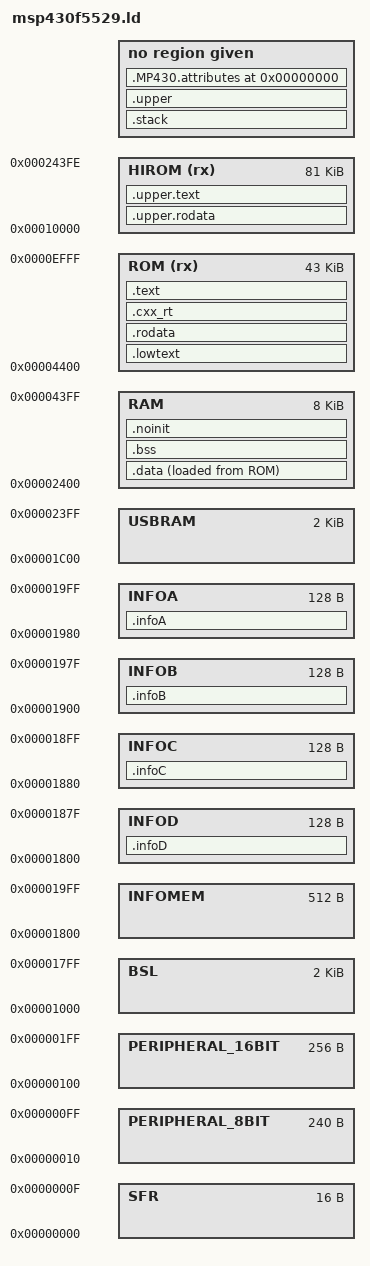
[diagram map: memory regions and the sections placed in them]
/* ============================================================================ */
/* Copyright (c) 2015, Texas Instruments Incorporated                           */
/*  All rights reserved.                                                        */
/*                                                                              */
/*  Redistribution and use in source and binary forms, with or without          */
/*  modification, are permitted provided that the following conditions          */
/*  are met:                                                                    */
/*                                                                              */
/*  *  Redistributions of source code must retain the above copyright           */
/*     notice, this list of conditions and the following disclaimer.            */
/*                                                                              */
/*  *  Redistributions in binary form must reproduce the above copyright        */
/*     notice, this list of conditions and the following disclaimer in the      */
/*     documentation and/or other materials provided with the distribution.     */
/*                                                                              */
/*  *  Neither the name of Texas Instruments Incorporated nor the names of      */
/*     its contributors may be used to endorse or promote products derived      */
/*     from this software without specific prior written permission.            */
/*                                                                              */
/*  THIS SOFTWARE IS PROVIDED BY THE COPYRIGHT HOLDERS AND CONTRIBUTORS "AS IS" */
/*  AND ANY EXPRESS OR IMPLIED WARRANTIES, INCLUDING, BUT NOT LIMITED TO,       */
/*  THE IMPLIED WARRANTIES OF MERCHANTABILITY AND FITNESS FOR A PARTICULAR      */
/*  PURPOSE ARE DISCLAIMED. IN NO EVENT SHALL THE COPYRIGHT OWNER OR            */
/*  CONTRIBUTORS BE LIABLE FOR ANY DIRECT, INDIRECT, INCIDENTAL, SPECIAL,       */
/*  EXEMPLARY, OR CONSEQUENTIAL DAMAGES (INCLUDING, BUT NOT LIMITED TO,         */
/*  PROCUREMENT OF SUBSTITUTE GOODS OR SERVICES; LOSS OF USE, DATA, OR PROFITS; */
/*  OR BUSINESS INTERRUPTION) HOWEVER CAUSED AND ON ANY THEORY OF LIABILITY,    */
/*  WHETHER IN CONTRACT, STRICT LIABILITY, OR TORT (INCLUDING NEGLIGENCE OR     */
/*  OTHERWISE) ARISING IN ANY WAY OUT OF THE USE OF THIS SOFTWARE,              */
/*  EVEN IF ADVISED OF THE POSSIBILITY OF SUCH DAMAGE.                          */
/* ============================================================================ */

/* This file supports MSP430F5529 devices. */
/* Version: 1.159 */
/* Default linker script, for normal executables */

OUTPUT_ARCH(msp430)
ENTRY(_start)

MEMORY {
  SFR              : ORIGIN = 0x0000, LENGTH = 0x0010 /* END=0x0010, size 16 */
  PERIPHERAL_8BIT  : ORIGIN = 0x0010, LENGTH = 0x00F0 /* END=0x0100, size 240 */
  PERIPHERAL_16BIT : ORIGIN = 0x0100, LENGTH = 0x0100 /* END=0x0200, size 256 */
  RAM              : ORIGIN = 0x2400, LENGTH = 0x2000 /* END=0x43FF, size 8192 */
  INFOMEM          : ORIGIN = 0x1800, LENGTH = 0x0200 /* END=0x19FF, size 512 as 4 128-byte segments */
  INFOA            : ORIGIN = 0x1980, LENGTH = 0x0080 /* END=0x19FF, size 128 */
  INFOB            : ORIGIN = 0x1900, LENGTH = 0x0080 /* END=0x197F, size 128 */
  INFOC            : ORIGIN = 0x1880, LENGTH = 0x0080 /* END=0x18FF, size 128 */
  INFOD            : ORIGIN = 0x1800, LENGTH = 0x0080 /* END=0x187F, size 128 */
  ROM (rx)       : ORIGIN = 0x4400, LENGTH = 0xac00 /* END=0xF3FF, size 44032 */
  BSL              : ORIGIN = 0x1000, LENGTH = 0x0800
  USBRAM           : ORIGIN = 0x1C00, LENGTH = 0x0800
  HIROM (rx)     : ORIGIN = 0x00010000, LENGTH = 0x000143FF
}

SECTIONS
{
  /* This is just for crt0.S and interrupt handlers.  */
  .lowtext           :
  {
    PROVIDE (_start = .);
    . = ALIGN(2);
    KEEP (*(SORT(.crt_*)))
    . = ALIGN(2);
    KEEP (*(.lowtext))
  } > ROM

  .rodata :
  {
    . = ALIGN(2);
    *(.plt)
    . = ALIGN(2);
    *(.lower.rodata.* .lower.rodata)
    . = ALIGN(2);
    *(.rodata .rodata.* .gnu.linkonce.r.* .const .const:*)
    . = ALIGN(2);
    *(.rodata1)

  } > ROM

  .cxx_rt :
  {
    . = ALIGN(2);
    *(.eh_frame_hdr)
    . = ALIGN(2);
    KEEP (*(.eh_frame))
    . = ALIGN(2);
    KEEP (*(.gcc_except_table)) *(.gcc_except_table.*)
    . = ALIGN(2);
    PROVIDE (__preinit_array_start = .);
    . = ALIGN(2);
    KEEP (*(.preinit_array))
    . = ALIGN(2);
    PROVIDE (__preinit_array_end = .);
    . = ALIGN(2);
    PROVIDE (__init_array_start = .);
    . = ALIGN(2);
    KEEP (*(SORT(.init_array.*)))
    . = ALIGN(2);
    KEEP (*(.init_array))
    . = ALIGN(2);
    PROVIDE (__init_array_end = .);
    . = ALIGN(2);
    PROVIDE (__fini_array_start = .);
    . = ALIGN(2);
    KEEP (*(.fini_array))
    . = ALIGN(2);
    KEEP (*(SORT(.fini_array.*)))
    . = ALIGN(2);
    PROVIDE (__fini_array_end = .);
    . = ALIGN(2);
    LONG(0); /* Sentinel.  */
    . = ALIGN(2);

    /* gcc uses crtbegin.o to find the start of the constructors, so
       we make sure it is first.  Because this is a wildcard, it
       doesn't matter if the user does not actually link against
       crtbegin.o; the linker won't look for a file to match a
       wildcard.  The wildcard also means that it doesn't matter which
       directory crtbegin.o is in.  */
    KEEP (*crtbegin*.o(.ctors))
    . = ALIGN(2);

    /* We don't want to include the .ctor section from from the
       crtend.o file until after the sorted ctors.  The .ctor section
       from the crtend file contains the end of ctors marker and it
       must be last */
    KEEP (*(EXCLUDE_FILE (*crtend*.o ) .ctors))
    . = ALIGN(2);
    KEEP (*(SORT(.ctors.*)))
    . = ALIGN(2);
    KEEP (*(.ctors))
    . = ALIGN(2);

    KEEP (*crtbegin*.o(.dtors))
    . = ALIGN(2);
    KEEP (*(EXCLUDE_FILE (*crtend*.o ) .dtors))
    . = ALIGN(2);
    KEEP (*(SORT(.dtors.*)))
    . = ALIGN(2);
    KEEP (*(.dtors))
  } > ROM

  .upper.rodata :
  {
    . = ALIGN(2);
    *(.upper.rodata.* .upper.rodata)
  } > HIROM

  .data :
  {
    . = ALIGN(2);
    PROVIDE (__datastart = .);
    *(.lower.data.* .lower.data)

    . = ALIGN(2);
    *(.either.data.* .either.data)

    . = ALIGN(2);
    KEEP (*(.jcr))
    . = ALIGN(2);
    *(.data.rel.ro.local) *(.data.rel.ro*)
    . = ALIGN(2);
    *(.dynamic)

    . = ALIGN(2);
    *(.data .data.* .gnu.linkonce.d.*)
    . = ALIGN(2);
    KEEP (*(.gnu.linkonce.d.*personality*))
    . = ALIGN(2);
    SORT(CONSTRUCTORS)
    . = ALIGN(2);
    *(.data1)
    . = ALIGN(2);
    *(.got.plt) *(.got)
    . = ALIGN(2);

    /* We want the small data sections together, so single-instruction offsets
       can access them all, and initialized data all before uninitialized, so
       we can shorten the on-disk segment size.  */
    . = ALIGN(2);
    *(.sdata .sdata.* .gnu.linkonce.s.* D_2 D_1)

    . = ALIGN(2);
    _edata = .;
    PROVIDE (edata = .);
    PROVIDE (__dataend = .);
  } > RAM AT> ROM

  /* Note that crt0 assumes this is a multiple of two; all the
     start/stop symbols are also assumed word-aligned.  */
  PROVIDE(__romdatastart = LOADADDR(.data));
  PROVIDE (__romdatacopysize = SIZEOF(.data));

  .bss :
  {
    . = ALIGN(2);
    PROVIDE (__bssstart = .);
    *(.lower.bss.* .lower.bss)
    . = ALIGN(2);
    *(.either.bss.* .either.bss)
    . = ALIGN(2);
    *(.dynbss)
    . = ALIGN(2);
    *(.sbss .sbss.*)
    . = ALIGN(2);
    *(.bss .bss.* .gnu.linkonce.b.*)
    . = ALIGN(2);
    *(COMMON)
    PROVIDE (__bssend = .);
  } > RAM
  PROVIDE (__bsssize = SIZEOF(.bss));

  /* This section contains data that is not initialised at startup.  */
  .noinit :
  {
    . = ALIGN(2);
    PROVIDE (__noinit_start = .);
    *(.noinit)
    . = ALIGN(2);
    PROVIDE (__noinit_end = .);
  } > RAM

  _end = .;
  PROVIDE (end = .);

  .stack (ORIGIN (RAM) + LENGTH(RAM)) :
  {
    PROVIDE (__stack = .);
    *(.stack)
  }


  .text :
  {
    . = ALIGN(2);
    *(.lower.text.* .lower.text)

    . = ALIGN(2);
    *(.text .stub .text.* .gnu.linkonce.t.* .text:*)

    KEEP (*(.text.*personality*))
    /* .gnu.warning sections are handled specially by elf32.em.  */
    *(.gnu.warning)
    *(.interp .hash .dynsym .dynstr .gnu.version*)
    PROVIDE (__etext = .);
    PROVIDE (_etext = .);
    PROVIDE (etext = .);
    . = ALIGN(2);
    KEEP (*(.init))
    KEEP (*(.fini))
    KEEP (*(.tm_clone_table))
  } > ROM

  .upper.text :
  {
    . = ALIGN(2);
    *(.upper.text.* .upper.text)
  } > HIROM

  .infoA     : {} > INFOA              /* MSP430 INFO FLASH MEMORY SEGMENTS */
  .infoB     : {} > INFOB
  .infoC     : {} > INFOC
  .infoD     : {} > INFOD

  /* Make sure that upper data sections are not used.  */
  .upper :
  {
    *(.upper.bss.* .upper.bss)
    *(.upper.data.* .upper.data)
    ASSERT (SIZEOF(.upper) == 0, "This MCU does not support placing read/write data into high memory");
  }

  /* The rest are all not normally part of the runtime image.  */

  .MP430.attributes 0 :
  {
    KEEP (*(.MSP430.attributes))
    KEEP (*(.gnu.attributes))
    KEEP (*(__TI_build_attributes))
  }

  /* Stabs debugging sections.  */
  .stab          0 : { *(.stab) }
  .stabstr       0 : { *(.stabstr) }
  .stab.excl     0 : { *(.stab.excl) }
  .stab.exclstr  0 : { *(.stab.exclstr) }
  .stab.index    0 : { *(.stab.index) }
  .stab.indexstr 0 : { *(.stab.indexstr) }
  .comment       0 : { *(.comment) }
  /* DWARF debug sections.
     Symbols in the DWARF debugging sections are relative to the beginning
     of the section so we begin them at 0.  */
  /* DWARF 1.  */
  .debug          0 : { *(.debug) }
  .line           0 : { *(.line) }
  /* GNU DWARF 1 extensions.  */
  .debug_srcinfo  0 : { *(.debug_srcinfo) }
  .debug_sfnames  0 : { *(.debug_sfnames) }
  /* DWARF 1.1 and DWARF 2.  */
  .debug_aranges  0 : { *(.debug_aranges) }
  .debug_pubnames 0 : { *(.debug_pubnames) }
  /* DWARF 2.  */
  .debug_info     0 : { *(.debug_info .gnu.linkonce.wi.*) }
  .debug_abbrev   0 : { *(.debug_abbrev) }
  .debug_line     0 : { *(.debug_line .debug_line.* .debug_line_end ) }
  .debug_frame    0 : { *(.debug_frame) }
  .debug_str      0 : { *(.debug_str) }
  .debug_loc      0 : { *(.debug_loc) }
  .debug_macinfo  0 : { *(.debug_macinfo) }
  /* SGI/MIPS DWARF 2 extensions.  */
  .debug_weaknames 0 : { *(.debug_weaknames) }
  .debug_funcnames 0 : { *(.debug_funcnames) }
  .debug_typenames 0 : { *(.debug_typenames) }
  .debug_varnames  0 : { *(.debug_varnames) }
  /* DWARF 3 */
  .debug_pubtypes 0 : { *(.debug_pubtypes) }
  .debug_ranges   0 : { *(.debug_ranges) }
  /* DWARF Extension.  */
  .debug_macro    0 : { *(.debug_macro) }

  /DISCARD/ : { *(.note.GNU-stack) }
}

